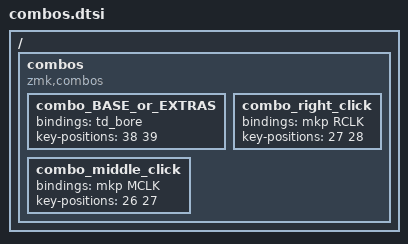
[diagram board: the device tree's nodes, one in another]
/ {
    combos {
        compatible = "zmk,combos";

        combo_BASE_or_EXTRAS {
            bindings = <&td_bore>;
            key-positions = <38 39>;
        };
        
        combo_middle_click {
            bindings = <&mkp MCLK>;
            key-positions = <26 27>;
        };

        combo_right_click {
            bindings = <&mkp RCLK>;
            key-positions = <27 28>;
        };
    };
};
